# STM32H73x register map
File version: 1.0
CPU: CM7 r0p1, little endian, MPU, FPU, 4 interrupt priority bits
Registers are 32-bit, read-write, reset 0x0 unless marked. A register's access mark holds for its fields unless they carry their own. Offsets are from the block's base; [hi:lo] are bit positions; {n}, {i} and the like mark numbered series; 'fields as' and 'values as' point back to an identical list.

## DBGMCU — Microcontroller Debug Unit
Base 0x5C001000
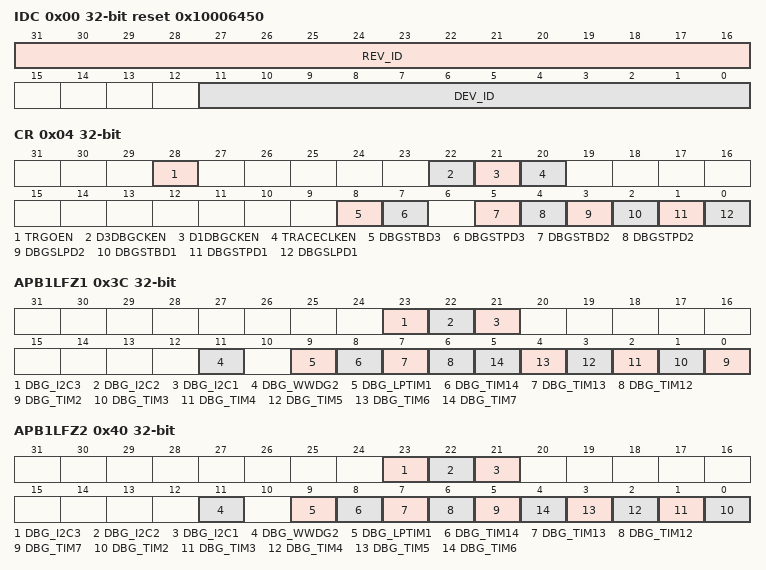
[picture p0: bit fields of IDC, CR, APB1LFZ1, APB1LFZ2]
0x00 IDC ro reset 0x10006450 — DBGMCU Identity Code Register
  [31:16] REV_ID — Revision
  [11:0] DEV_ID — Device ID
0x04 CR — DBGMCU Configuration Register
  [28] TRGOEN — External trigger output enable
  [22] D3DBGCKEN — D3 debug clock enable
  [21] D1DBGCKEN — D1 debug clock enable
  [20] TRACECLKEN — Trace port clock enable
  [8] DBGSTBD3 — Allow debug in D3 Standby mode
  [7] DBGSTPD3 — Allow debug in D3 Stop mode
  [5] DBGSTBD2 — Allow D2 domain debug in Standby mode
  [4] DBGSTPD2 — Allow D2 domain debug in Stop mode
  [3] DBGSLPD2 — Allow D2 domain debug in Sleep mode
  [2] DBGSTBD1 — Allow D1 domain debug in Standby mode
  [1] DBGSTPD1 — Allow D1 domain debug in Stop mode
  [0] DBGSLPD1 — Allow D1 domain debug in Sleep mode
0x34 APB3FZ1 — DBGMCU APB3 peripheral freeze register CPU1
  [6] WWDG1 — WWDG1 stop in debug
0x38 APB3FZ2 — DBGMCU APB3 peripheral freeze register CPU2
  [6] WWDG1 — WWDG1 stop in debug
0x3C APB1LFZ1 — DBGMCU APB1L peripheral freeze register
  [23] DBG_I2C3 — I2C3 SMBUS timeout stop in debug
  [22] DBG_I2C2 — I2C2 SMBUS timeout stop in debug
  [21] DBG_I2C1 — I2C1 SMBUS timeout stop in debug
  [11] DBG_WWDG2 — WWDG2 stop in debug
  [9] DBG_LPTIM1 — LPTIM1 stop in debug
  [8] DBG_TIM14 — TIM14 stop in debug
  [7] DBG_TIM13 — TIM13 stop in debug
  [6] DBG_TIM12 — TIM12 stop in debug
  [n-2] DBG_TIM{n} (n=2..7) — TIM{n} stop in debug
0x40 APB1LFZ2 — DBGMCU APB1L peripheral freeze register CPU2
  [23] DBG_I2C3 — I2C3 SMBUS timeout stop in debug
  [22] DBG_I2C2 — I2C2 SMBUS timeout stop in debug
  [21] DBG_I2C1 — I2C1 SMBUS timeout stop in debug
  [11] DBG_WWDG2 — WWDG2 stop in debug
  [9] DBG_LPTIM1 — LPTIM1 stop in debug
  [8] DBG_TIM14 — TIM14 stop in debug
  [7] DBG_TIM13 — TIM13 stop in debug
  [6] DBG_TIM12 — TIM12 stop in debug
  [5] DBG_TIM7 — TIM4 stop in debug
  [n-2] DBG_TIM{n} (n=2..6) — TIM{n} stop in debug
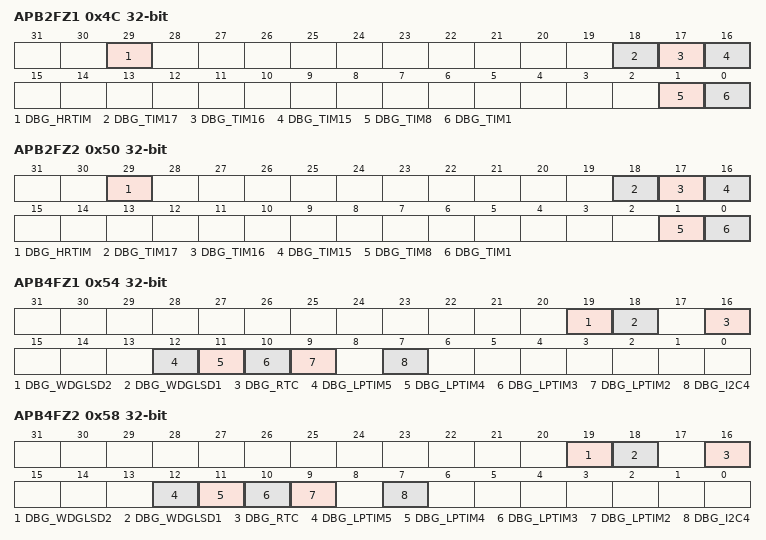
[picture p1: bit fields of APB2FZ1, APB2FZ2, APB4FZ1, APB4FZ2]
0x4C APB2FZ1 — DBGMCU APB2 peripheral freeze register
  [29] DBG_HRTIM — HRTIM stop in debug
  [18] DBG_TIM17 — TIM17 stop in debug
  [17] DBG_TIM16 — TIM16 stop in debug
  [16] DBG_TIM15 — TIM15 stop in debug
  [1] DBG_TIM8 — TIM8 stop in debug
  [0] DBG_TIM1 — TIM1 stop in debug
0x50 APB2FZ2 — DBGMCU APB2 peripheral freeze register CPU2
  fields as APB2FZ1
0x54 APB4FZ1 — DBGMCU APB4 peripheral freeze register
  [19] DBG_WDGLSD2 — Independent watchdog for D2 stop in debug
  [18] DBG_WDGLSD1 — Independent watchdog for D1 stop in debug
  [16] DBG_RTC — RTC stop in debug
  [12] DBG_LPTIM5 — LPTIM5 stop in debug
  [11] DBG_LPTIM4 — LPTIM4 stop in debug
  [10] DBG_LPTIM3 — LPTIM2 stop in debug
  [9] DBG_LPTIM2 — LPTIM2 stop in debug
  [7] DBG_I2C4 — I2C4 SMBUS timeout stop in debug
0x58 APB4FZ2 — DBGMCU APB4 peripheral freeze register CPU2
  [19] DBG_WDGLSD2 — LS watchdog for D2 stop in debug
  [18] DBG_WDGLSD1 — LS watchdog for D1 stop in debug
  [16] DBG_RTC — RTC stop in debug
  [12] DBG_LPTIM5 — LPTIM5 stop in debug
  [11] DBG_LPTIM4 — LPTIM4 stop in debug
  [10] DBG_LPTIM3 — LPTIM2 stop in debug
  [9] DBG_LPTIM2 — LPTIM2 stop in debug
  [7] DBG_I2C4 — I2C4 SMBUS timeout stop in debug

## MPU — Memory protection unit
Base 0xE000ED90
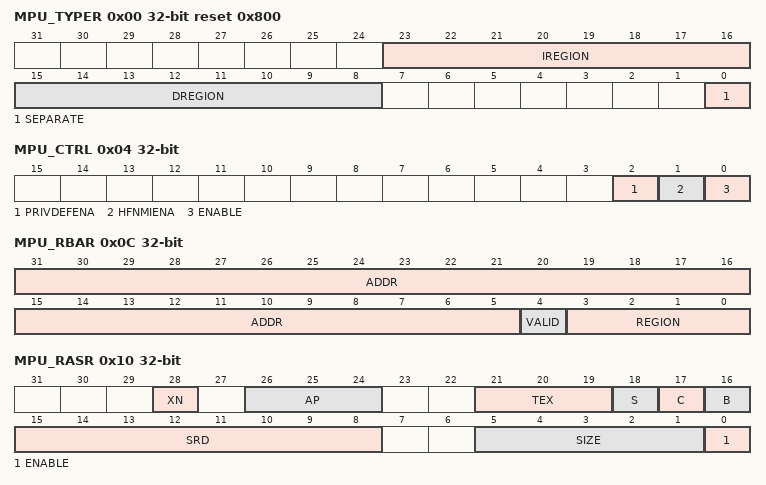
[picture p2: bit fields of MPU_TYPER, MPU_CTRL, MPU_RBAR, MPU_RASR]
0x00 MPU_TYPER ro reset 0x800 — MPU type register
  [23:16] IREGION — Number of MPU instruction regions
  [15:8] DREGION — Number of MPU data regions
  [0] SEPARATE — Separate flag
0x04 MPU_CTRL — MPU control register
  [2] PRIVDEFENA — Enable priviliged software access to default memory map
  [1] HFNMIENA — Enables the operation of MPU during hard fault
  [0] ENABLE — Enables the MPU
0x08 MPU_RNR — MPU region number register
  [7:0] REGION — MPU region
0x0C MPU_RBAR — MPU region base address register
  [31:5] ADDR — Region base address field
  [4] VALID — MPU region number valid
  [3:0] REGION — MPU region field
0x10 MPU_RASR — MPU region attribute and size register
  [28] XN — Instruction access disable bit
  [26:24] AP — Access permission
  [21:19] TEX — memory attribute
  [18] S — Shareable memory attribute
  [17] C — memory attribute
  [16] B — memory attribute
  [15:8] SRD — Subregion disable bits
  [5:1] SIZE — Size of the MPU protection region
  [0] ENABLE — Region enable bit.
